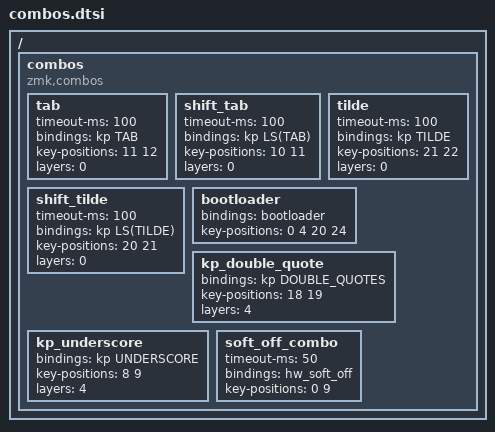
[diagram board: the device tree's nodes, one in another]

/ {
    combos {
        compatible = "zmk,combos";

        tab {
            timeout-ms = <100>;
            bindings = <&kp TAB>;
            key-positions = <11 12>;
            layers = <0>;
        };

        shift_tab{
            timeout-ms = <100>;
            bindings = <&kp LS(TAB)>;
            key-positions = <10 11>;
            layers = <0>;
        };

        tilde{
            timeout-ms = <100>;
            bindings = <&kp TILDE>;
            key-positions = <21 22>;
            layers = <0>;
        };

        shift_tilde{
            timeout-ms = <100>;
            bindings = <&kp LS(TILDE)>;
            key-positions = <20 21>;
            layers = <0>;
        };

        bootloader {
            bindings = <&bootloader>;
            key-positions = <0 4 20 24>;
        };

        kp_double_quote {
            bindings = <&kp DOUBLE_QUOTES>;
            key-positions = <18 19>;
            layers = <4>;
        };

        kp_underscore {
            bindings = <&kp UNDERSCORE>;
            key-positions = <8 9>;
            layers = <4>;
        };

        soft_off_combo {
            timeout-ms = <50>;
            bindings = <&hw_soft_off>;
            key-positions = <0 9>;  // Top left + top right corner keys (Q + SEMICOLON)
        };
    };
};
